# MISC_ANALOG_CTRL register map
Vendor: Texas Instruments
Peripheral module from a debugger description file (folder ucd3138128A).
Registers are 32-bit, access not given, no defined reset value unless marked. A register's access mark holds for its fields unless they carry their own. Offsets are as the file gives them; lines under a group give offsets from that group; [hi:lo] are bit positions; {n}, {i} and the like mark numbered series; 'fields as' and 'values as' point back to an identical list; <NAME> marks a mode.

## MISCANALOG
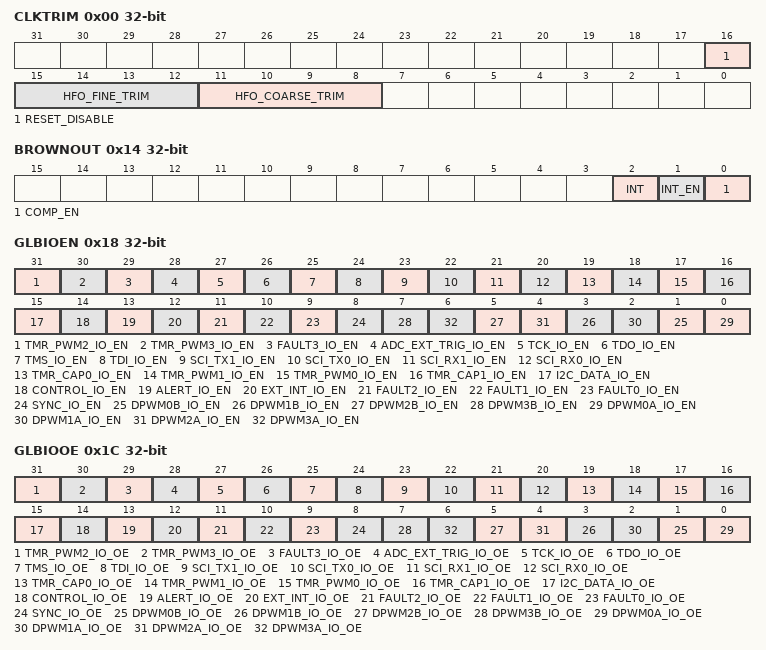
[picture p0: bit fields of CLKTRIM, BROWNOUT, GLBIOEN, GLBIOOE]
0x00 CLKTRIM
  [16] RESET_DISABLE rw — RESET Pin Disable bit
  [15:12] HFO_FINE_TRIM rw
  [11:8] HFO_COARSE_TRIM rw
0x14 BROWNOUT
  [2] INT ro — Brownout Interrupt Latched Status
  [1] INT_EN rw — Brownout Interrupt Enable
  [0] COMP_EN rw — Brownout Enable
0x18 GLBIOEN rw
  [31] TMR_PWM2_IO_EN — bit 31
  [30] TMR_PWM3_IO_EN — bit 30
  [29] FAULT3_IO_EN — bit 29
  [28] ADC_EXT_TRIG_IO_EN — bit 28
  [27] TCK_IO_EN — bit 27
  [26] TDO_IO_EN — bit 26
  [25] TMS_IO_EN — bit 25
  [24] TDI_IO_EN — bit 24
  [23] SCI_TX1_IO_EN — bit 23
  [22] SCI_TX0_IO_EN — bit 22
  [21] SCI_RX1_IO_EN — bit 21
  [20] SCI_RX0_IO_EN — bit 20
  [19] TMR_CAP0_IO_EN — bit 19
  [18] TMR_PWM1_IO_EN — bit 18
  [17] TMR_PWM0_IO_EN — bit 17
  [16] TMR_CAP1_IO_EN — bit 16
  [15] I2C_DATA_IO_EN — bit 15
  [14] CONTROL_IO_EN — bit 14
  [13] ALERT_IO_EN — bit 13
  [12] EXT_INT_IO_EN — bit 12
  [11] FAULT2_IO_EN — bit 11
  [10] FAULT1_IO_EN — bit 10
  [9] FAULT0_IO_EN — bit 9
  [8] SYNC_IO_EN — bit 8
  [2n+1] DPWM{n}B_IO_EN (n=0..3) — bit {2n+1}
  [2n] DPWM{n}A_IO_EN (n=0..3) — bit {2n}
0x1C GLBIOOE rw
  [31] TMR_PWM2_IO_OE — bit 31
  [30] TMR_PWM3_IO_OE — bit 30
  [29] FAULT3_IO_OE — bit 29
  [28] ADC_EXT_TRIG_IO_OE — bit 28
  [27] TCK_IO_OE — bit 27
  [26] TDO_IO_OE — bit 26
  [25] TMS_IO_OE — bit 25
  [24] TDI_IO_OE — bit 24
  [23] SCI_TX1_IO_OE — bit 23
  [22] SCI_TX0_IO_OE — bit 22
  [21] SCI_RX1_IO_OE — bit 21
  [20] SCI_RX0_IO_OE — bit 20
  [19] TMR_CAP0_IO_OE — bit 19
  [18] TMR_PWM1_IO_OE — bit 18
  [17] TMR_PWM0_IO_OE — bit 17
  [16] TMR_CAP1_IO_OE — bit 16
  [15] I2C_DATA_IO_OE — bit 15
  [14] CONTROL_IO_OE — bit 14
  [13] ALERT_IO_OE — bit 13
  [12] EXT_INT_IO_OE — bit 12
  [11] FAULT2_IO_OE — bit 11
  [10] FAULT1_IO_OE — bit 10
  [9] FAULT0_IO_OE — bit 9
  [8] SYNC_IO_OE — bit 8
  [2n+1] DPWM{n}B_IO_OE (n=0..3) — bit {2n+1}
  [2n] DPWM{n}A_IO_OE (n=0..3) — bit {2n}
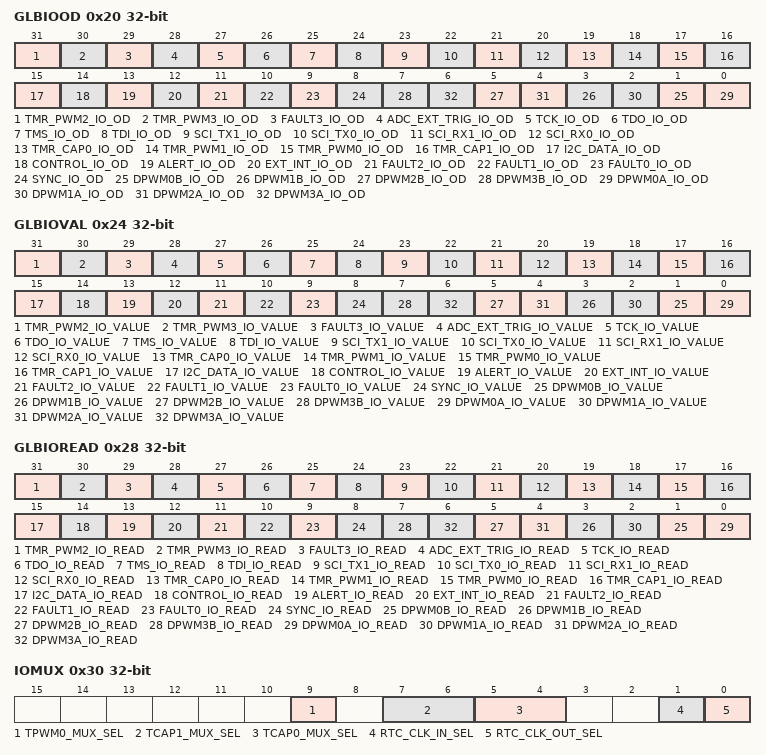
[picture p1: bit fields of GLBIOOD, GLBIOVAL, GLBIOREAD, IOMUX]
0x20 GLBIOOD rw
  [31] TMR_PWM2_IO_OD — bit 31
  [30] TMR_PWM3_IO_OD — bit 30
  [29] FAULT3_IO_OD — bit 29
  [28] ADC_EXT_TRIG_IO_OD — bit 28
  [27] TCK_IO_OD — bit 27
  [26] TDO_IO_OD — bit 26
  [25] TMS_IO_OD — bit 25
  [24] TDI_IO_OD — bit 24
  [23] SCI_TX1_IO_OD — bit 23
  [22] SCI_TX0_IO_OD — bit 22
  [21] SCI_RX1_IO_OD — bit 21
  [20] SCI_RX0_IO_OD — bit 20
  [19] TMR_CAP0_IO_OD — bit 19
  [18] TMR_PWM1_IO_OD — bit 18
  [17] TMR_PWM0_IO_OD — bit 17
  [16] TMR_CAP1_IO_OD — bit 16
  [15] I2C_DATA_IO_OD — bit 15
  [14] CONTROL_IO_OD — bit 14
  [13] ALERT_IO_OD — bit 13
  [12] EXT_INT_IO_OD — bit 12
  [11] FAULT2_IO_OD — bit 11
  [10] FAULT1_IO_OD — bit 10
  [9] FAULT0_IO_OD — bit 9
  [8] SYNC_IO_OD — bit 8
  [2n+1] DPWM{n}B_IO_OD (n=0..3) — bit {2n+1}
  [2n] DPWM{n}A_IO_OD (n=0..3) — bit {2n}
0x24 GLBIOVAL rw
  [31] TMR_PWM2_IO_VALUE — bit 31
  [30] TMR_PWM3_IO_VALUE — bit 30
  [29] FAULT3_IO_VALUE — bit 29
  [28] ADC_EXT_TRIG_IO_VALUE — bit 28
  [27] TCK_IO_VALUE — bit 27
  [26] TDO_IO_VALUE — bit 26
  [25] TMS_IO_VALUE — bit 25
  [24] TDI_IO_VALUE — bit 24
  [23] SCI_TX1_IO_VALUE — bit 23
  [22] SCI_TX0_IO_VALUE — bit 22
  [21] SCI_RX1_IO_VALUE — bit 21
  [20] SCI_RX0_IO_VALUE — bit 20
  [19] TMR_CAP0_IO_VALUE — bit 19
  [18] TMR_PWM1_IO_VALUE — bit 18
  [17] TMR_PWM0_IO_VALUE — bit 17
  [16] TMR_CAP1_IO_VALUE — bit 16
  [15] I2C_DATA_IO_VALUE — bit 15
  [14] CONTROL_IO_VALUE — bit 14
  [13] ALERT_IO_VALUE — bit 13
  [12] EXT_INT_IO_VALUE — bit 12
  [11] FAULT2_IO_VALUE — bit 11
  [10] FAULT1_IO_VALUE — bit 10
  [9] FAULT0_IO_VALUE — bit 9
  [8] SYNC_IO_VALUE — bit 8
  [2n+1] DPWM{n}B_IO_VALUE (n=0..3) — bit {2n+1}
  [2n] DPWM{n}A_IO_VALUE (n=0..3) — bit {2n}
0x28 GLBIOREAD ro
  [31] TMR_PWM2_IO_READ — bit 31
  [30] TMR_PWM3_IO_READ — bit 30
  [29] FAULT3_IO_READ — bit 29
  [28] ADC_EXT_TRIG_IO_READ — bit 28
  [27] TCK_IO_READ — bit 27
  [26] TDO_IO_READ — bit 26
  [25] TMS_IO_READ — bit 25
  [24] TDI_IO_READ — bit 24
  [23] SCI_TX1_IO_READ — bit 23
  [22] SCI_TX0_IO_READ — bit 22
  [21] SCI_RX1_IO_READ — bit 21
  [20] SCI_RX0_IO_READ — bit 20
  [19] TMR_CAP0_IO_READ — bit 19
  [18] TMR_PWM1_IO_READ — bit 18
  [17] TMR_PWM0_IO_READ — bit 17
  [16] TMR_CAP1_IO_READ — bit 16
  [15] I2C_DATA_IO_READ — bit 15
  [14] CONTROL_IO_READ — bit 14
  [13] ALERT_IO_READ — bit 13
  [12] EXT_INT_IO_READ — bit 12
  [11] FAULT2_IO_READ — bit 11
  [10] FAULT1_IO_READ — bit 10
  [9] FAULT0_IO_READ — bit 9
  [8] SYNC_IO_READ — bit 8
  [2n+1] DPWM{n}B_IO_READ (n=0..3) — bit {2n+1}
  [2n] DPWM{n}A_IO_READ (n=0..3) — bit {2n}
0x30 IOMUX
  [9] TPWM0_MUX_SEL rw — TPWM0 Pins Mux Control
  [7:6] TCAP1_MUX_SEL rw — TCAP1 Pins Mux Control
  [5:4] TCAP0_MUX_SEL rw — TCAP0 Data Pins Mux Control
  [1] RTC_CLK_IN_SEL rw — RTC clock in mux select
  [0] RTC_CLK_OUT_SEL rw — RTC clock out mux select
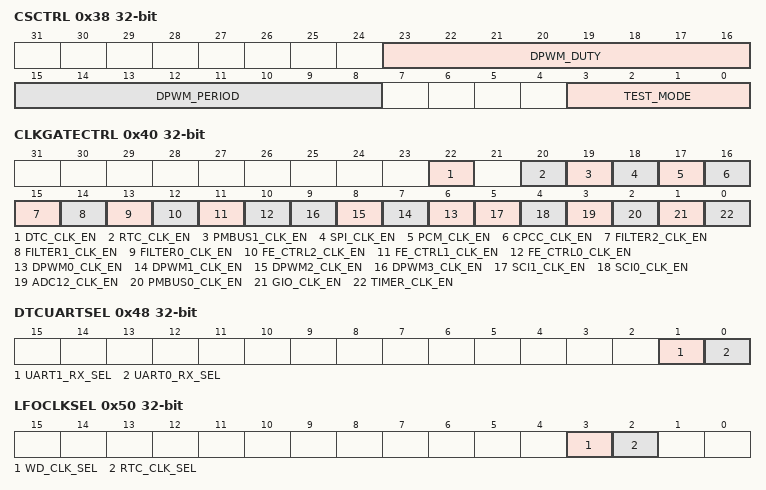
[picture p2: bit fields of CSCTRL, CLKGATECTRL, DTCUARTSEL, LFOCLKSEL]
0x38 CSCTRL
  [23:16] DPWM_DUTY rw — DPWM Duty/Pulse Width for Cur Share
  [15:8] DPWM_PERIOD rw — DPWM Period for Current Share
  [3:0] TEST_MODE rw — Current Sharing Test Mode
0x3C TEMPREF
  [11:0] TEMP_REF rw — Temperature Reference
0x40 CLKGATECTRL
  [22] DTC_CLK_EN rw — DTC Clock Enable
  [20] RTC_CLK_EN rw — RTC Clock Enable
  [19] PMBUS1_CLK_EN rw — PMBus 1 I/F Clock Enable
  [18] SPI_CLK_EN rw — SPI I/F Clock Enable
  [17] PCM_CLK_EN rw — Peak Current Mode Clock Enable
  [16] CPCC_CLK_EN rw — Constant Power/Constant Current Clock Enable
  [15] FILTER2_CLK_EN rw — Filter 2 Clock Enable
  [14] FILTER1_CLK_EN rw — Filter 1 Clock Enable
  [13] FILTER0_CLK_EN rw — Filter 0 Clock Enable
  [12] FE_CTRL2_CLK_EN rw — Front End Control 2 Clock Enable
  [11] FE_CTRL1_CLK_EN rw — Front End Control 2 Clock Enable
  [10] FE_CTRL0_CLK_EN rw — Front End Control 2 Clock Enable
  [n+6] DPWM{n}_CLK_EN rw (n=0..3) — DPWM4 Clock Enable
  [5] SCI1_CLK_EN rw — SCI1 Clock Enable
  [4] SCI0_CLK_EN rw — SCI0 Clock Enable
  [3] ADC12_CLK_EN rw — ADC12 Control Clock Enable
  [2] PMBUS0_CLK_EN rw — PMBus I/F Clock Enable
  [1] GIO_CLK_EN rw — GIO Clock Enable
  [0] TIMER_CLK_EN rw — Timer Clock Enable
0x48 DTCUARTSEL
  [1] UART1_RX_SEL rw — UART1 Receive Pin Control
  [0] UART0_RX_SEL rw — UART0 Receive Pin Control
0x50 LFOCLKSEL
  [3] WD_CLK_SEL rw, [2] RTC_CLK_SEL rw
